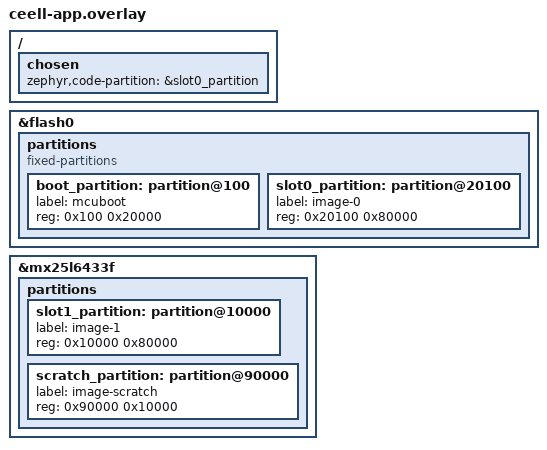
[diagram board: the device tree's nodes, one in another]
/* MCUboot flash layout for CEELL app image (sysbuild only)
 *
 * Applied on top of boards/mr_canhubk3.overlay.
 * Adds MCUboot partitions to internal flash and replaces the
 * large QSPI storage with slot1 + scratch + smaller storage.
 */

/* --- Internal flash: add MCUboot + slot0, replace code_partition --- */
&flash0 {
	partitions {
		compatible = "fixed-partitions";
		#address-cells = <1>;
		#size-cells = <1>;

		/* Delete the default code_partition from base DTS */
		/delete-node/ partition@100;

		boot_partition: partition@100 {
			label = "mcuboot";
			reg = <0x100 0x20000>;
		};

		slot0_partition: partition@20100 {
			label = "image-0";
			reg = <0x20100 0x80000>;
		};
	};
};

/* --- External QSPI: add slot1 + scratch after config_partition --- */
&mx25l6433f {
	partitions {
		/* Delete the large storage_partition from base overlay to
		 * free space for OTA partitions. Note: we cannot re-add
		 * storage_partition here due to DTS label conflict with
		 * the base overlay, but OTA builds don't need it. */
		/delete-node/ partition@10000;

		slot1_partition: partition@10000 {
			label = "image-1";
			reg = <0x10000 0x80000>;
		};

		scratch_partition: partition@90000 {
			label = "image-scratch";
			reg = <0x90000 0x10000>;
		};
	};
};

/* Point code-partition to slot0 for MCUboot chain boot */
/ {
	chosen {
		zephyr,code-partition = &slot0_partition;
	};
};
